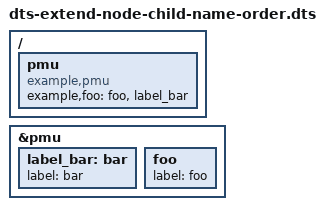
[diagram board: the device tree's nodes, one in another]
// SPDX-License-Identifier: GPL-2.0-only OR BSD-2-Clause
/dts-v1/;

/ {
	#address-cells = <1>;
	#size-cells = <1>;

	pmu {
		compatible = "example,pmu";

		/* Just reference labels to avoid strict warnings */
		example,foo = <&foo>, <&label_bar>;
	};
};

&pmu {
	/* Include labels to be sure they do not affect sorting */
	label_bar: bar {
		label = "bar";
	};

	foo: foo {
		label = "foo";
	};
};
